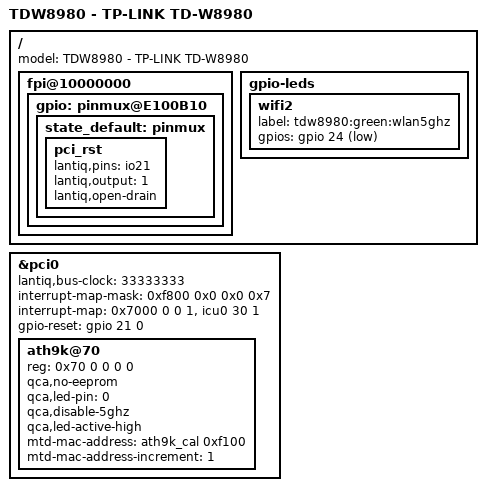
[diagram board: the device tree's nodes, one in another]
/dts-v1/;

/include/ "TDW89X0.dtsi"

/ {
	model = "TDW8980 - TP-LINK TD-W8980";

	fpi@10000000 {
		gpio: pinmux@E100B10 {
			state_default: pinmux {
				pci_rst {
					lantiq,pins = "io21";
					lantiq,output = <1>;
					lantiq,open-drain;
				};
			};
		};
	};

	gpio-leds {
		wifi2 {
			label = "tdw8980:green:wlan5ghz";
			gpios = <&gpio 24 1>;
		};
	};
};

&pci0 {
	status = "okay";
	lantiq,bus-clock = <33333333>;
	interrupt-map-mask = <0xf800 0x0 0x0 0x7>;
	interrupt-map = <0x7000 0 0 1 &icu0 30 1>;
	gpio-reset = <&gpio 21 0>;

	ath9k@70 {
		reg = <0x70 0 0 0 0>; /* slot 0xe (= 14) << 4 */
		device_type = "pci";
		qca,no-eeprom; /* load from ath9k-eeprom-pci-0000:00:0e.0.bin */
		qca,led-pin = <0>;
		qca,disable-5ghz;
		qca,led-active-high;
		mtd-mac-address = <&ath9k_cal 0xf100>;
		mtd-mac-address-increment = <1>;
	};
};
